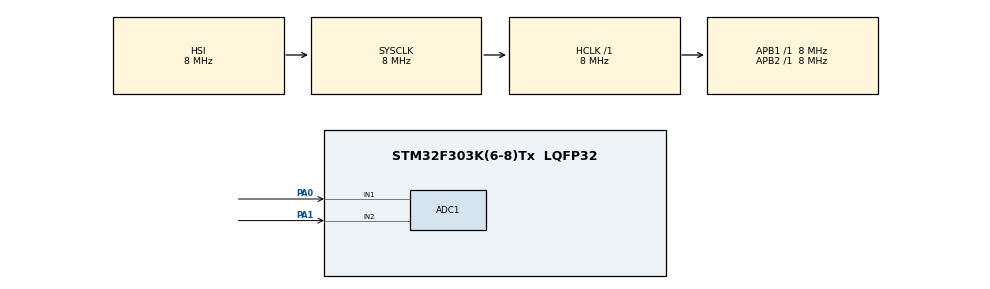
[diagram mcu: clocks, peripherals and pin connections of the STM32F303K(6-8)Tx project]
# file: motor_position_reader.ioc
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ADC1.Channel-0\#ChannelRegularConversion=ADC_CHANNEL_1
ADC1.Channel-2\#ChannelRegularConversion=ADC_CHANNEL_2
ADC1.ClockPrescaler=ADC_CLOCK_SYNC_PCLK_DIV1
ADC1.ContinuousConvMode=DISABLE
ADC1.DMAContinuousRequests=ENABLE
ADC1.EOCSelection=ADC_EOC_SEQ_CONV
ADC1.EnableAnalogWatchDog1=false
ADC1.EnableInjectedConversion=ENABLE
ADC1.ExternalTrigConv=ADC_EXTERNALTRIGCONV_T2_TRGO
ADC1.NbrOfConversion=2
ADC1.NbrOfConversionFlag=1
ADC1.Offset-0\#ChannelRegularConversion=0
ADC1.Offset-2\#ChannelRegularConversion=0
ADC1.OffsetNumber-0\#ChannelRegularConversion=ADC_OFFSET_NONE
ADC1.OffsetNumber-2\#ChannelRegularConversion=ADC_OFFSET_NONE
ADC1.Rank-0\#ChannelRegularConversion=1
ADC1.Rank-2\#ChannelRegularConversion=2
ADC1.SamplingTime-0\#ChannelRegularConversion=ADC_SAMPLETIME_19CYCLES_5
ADC1.SamplingTime-2\#ChannelRegularConversion=ADC_SAMPLETIME_19CYCLES_5
ADC1.SamplingTimeOPAMP-2\#ChannelRegularConversion=ADC_SAMPLETIME_4CYCLES_5
ADC1.SubFamily=STM32F303x8
ADC1.master=1
Dma.ADC1.0.Direction=DMA_PERIPH_TO_MEMORY
Dma.ADC1.0.Instance=DMA1_Channel1
Dma.ADC1.0.MemDataAlignment=DMA_MDATAALIGN_HALFWORD
Dma.ADC1.0.MemInc=DMA_MINC_ENABLE
Dma.ADC1.0.Mode=DMA_CIRCULAR
Dma.ADC1.0.PeriphDataAlignment=DMA_PDATAALIGN_HALFWORD
Dma.ADC1.0.PeriphInc=DMA_PINC_DISABLE
Dma.ADC1.0.Priority=DMA_PRIORITY_LOW
Dma.Request0=ADC1
Mcu.Family=STM32F3
Mcu.Name=STM32F303K(6-8)Tx
Mcu.Package=LQFP32
NVIC.DMA1_Channel1_IRQn=true\:0\:0\:false\:false\:true\:false\:true\:true
NVIC.PriorityGroup=NVIC_PRIORITYGROUP_4
PA0.Mode=IN1-Single-Ended
PA0.Signal=ADC1_IN1
PA1.Mode=IN2-Single-Ended
PA1.Signal=ADC1_IN2
PA13.Mode=Serial_Wire
PA13.Signal=SYS_JTMS-SWDIO
PA14.Mode=Serial_Wire
PA14.Signal=SYS_JTCK-SWCLK
ProjectManager.HeapSize=0x200
ProjectManager.StackSize=0x400
ProjectManager.TargetToolchain=STM32CubeIDE
RCC.AHBFreq_Value=8000000
RCC.APB1Freq_Value=8000000
RCC.APB2Freq_Value=8000000
RCC.CortexFreq_Value=8000000
RCC.HSE_VALUE=8000000
RCC.HSI_VALUE=8000000
RCC.SYSCLKFreq_VALUE=8000000
TIM2.Period=999
TIM2.Prescaler=7999
TIM2.TIM_MasterOutputTrigger=TIM_TRGO_UPDATE
TIM2.TIM_MasterSlaveMode=TIM_MASTERSLAVEMODE_ENABLE
VP_TIM2_VS_ClockSourceINT.Mode=Internal
board=custom

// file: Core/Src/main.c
/* USER CODE BEGIN Header */
/**
 ******************************************************************************
 * @file           : main.c
 * @brief          : Main program body
 ******************************************************************************
 * @attention
 *
 * Copyright (c) 2025 STMicroelectronics.
 * All rights reserved.
 *
 * This software is licensed under terms that can be found in the LICENSE file
 * in the root directory of this software component.
 * If no LICENSE file comes with this software, it is provided AS-IS.
 *
 ******************************************************************************
 */
/* USER CODE END Header */
#include "main.h"

/* USER CODE BEGIN PD */
#define ADC_BUF_SIZE	2
#define MOTOR_HISTORY_LEN	3 //PID only needs 3 max since it is at most second order
/* USER CODE END PD */

ADC_HandleTypeDef hadc1;
DMA_HandleTypeDef hdma_adc1;

TIM_HandleTypeDef htim2;

/* USER CODE BEGIN PV */
volatile uint8_t position_ready = 0; //flag representing whether or not position data is ready from adc
uint16_t raw_pos_values[ADC_BUF_SIZE];

uint16_t motor1_pos[MOTOR_HISTORY_LEN];
uint16_t motor2_pos[MOTOR_HISTORY_LEN];
/* USER CODE END PV */

void SystemClock_Config(void);
static void MX_GPIO_Init(void);
static void MX_DMA_Init(void);
static void MX_ADC1_Init(void);
static void MX_TIM2_Init(void);

int main(void)
{

	/* MCU Configuration--------------------------------------------------------*/

	/* Reset of all peripherals, Initializes the Flash interface and the Systick. */
	HAL_Init();

	/* Configure the system clock */
	SystemClock_Config();

	/* Initialize all configured peripherals */
	MX_GPIO_Init();
	MX_DMA_Init();
	MX_ADC1_Init();
	MX_TIM2_Init();
	/* USER CODE BEGIN 2 */
	if (HAL_TIM_Base_Start(&htim2) != HAL_OK)
	{
		Error_Handler();
	}

	if (HAL_ADCEx_Calibration_Start(&hadc1, ADC_SINGLE_ENDED) != HAL_OK) //calibrate ADC to get rid of offset error, Ex stands for extended. Special marking for function in HAL that might differ on other stm32 lines.
	{ //No Ex in HAL functions means you can easily copy code to other stm32 families.
		Error_Handler();
	}

	if (HAL_ADC_Start_DMA(&hadc1, (uint32_t*) raw_pos_values, 2) != HAL_OK)
	{
		Error_Handler();
	}
	/* USER CODE END 2 */

	/* Infinite loop */
	/* USER CODE BEGIN WHILE */
	while (1)
	{
		//The code updates the angle every 1 second, it is slow just for demo purposes. The analog output of the motor encoders will be connected to either pin A0 or A1.
		//The angle values will be in motor1_pos and motor2_pos. Must view live expressions and add these arrays to see the angles.
		while (!position_ready);
		position_ready = 0; //set flag back to 0

		/* USER CODE END WHILE */

	}
}

void SystemClock_Config(void)
{
	RCC_OscInitTypeDef RCC_OscInitStruct =
	{ 0 };
	RCC_ClkInitTypeDef RCC_ClkInitStruct =
	{ 0 };

	/** Initializes the RCC Oscillators according to the specified parameters
	 * in the RCC_OscInitTypeDef structure.
	 */
	RCC_OscInitStruct.OscillatorType = RCC_OSCILLATORTYPE_HSI;
	RCC_OscInitStruct.HSIState = RCC_HSI_ON;
	RCC_OscInitStruct.HSICalibrationValue = RCC_HSICALIBRATION_DEFAULT;
	RCC_OscInitStruct.PLL.PLLState = RCC_PLL_NONE;
	if (HAL_RCC_OscConfig(&RCC_OscInitStruct) != HAL_OK)
	{
		Error_Handler();
	}

	/** Initializes the CPU, AHB and APB buses clocks
	 */
	RCC_ClkInitStruct.ClockType = RCC_CLOCKTYPE_HCLK | RCC_CLOCKTYPE_SYSCLK
			| RCC_CLOCKTYPE_PCLK1 | RCC_CLOCKTYPE_PCLK2;
	RCC_ClkInitStruct.SYSCLKSource = RCC_SYSCLKSOURCE_HSI;
	RCC_ClkInitStruct.AHBCLKDivider = RCC_SYSCLK_DIV1;
	RCC_ClkInitStruct.APB1CLKDivider = RCC_HCLK_DIV1;
	RCC_ClkInitStruct.APB2CLKDivider = RCC_HCLK_DIV1;

	if (HAL_RCC_ClockConfig(&RCC_ClkInitStruct, FLASH_LATENCY_0) != HAL_OK)
	{
		Error_Handler();
	}
}

static void MX_ADC1_Init(void)
{

	ADC_MultiModeTypeDef multimode =
	{ 0 };
	ADC_ChannelConfTypeDef sConfig =
	{ 0 };

	/** Common config
	 */
	hadc1.Instance = ADC1;
	hadc1.Init.ClockPrescaler = ADC_CLOCK_SYNC_PCLK_DIV1;
	hadc1.Init.Resolution = ADC_RESOLUTION_12B;
	hadc1.Init.ScanConvMode = ADC_SCAN_ENABLE;
	hadc1.Init.ContinuousConvMode = DISABLE;
	hadc1.Init.DiscontinuousConvMode = DISABLE;
	hadc1.Init.ExternalTrigConvEdge = ADC_EXTERNALTRIGCONVEDGE_RISING;
	hadc1.Init.ExternalTrigConv = ADC_EXTERNALTRIGCONV_T2_TRGO;
	hadc1.Init.DataAlign = ADC_DATAALIGN_RIGHT;
	hadc1.Init.NbrOfConversion = 2;
	hadc1.Init.DMAContinuousRequests = ENABLE;
	hadc1.Init.EOCSelection = ADC_EOC_SEQ_CONV;
	hadc1.Init.LowPowerAutoWait = DISABLE;
	hadc1.Init.Overrun = ADC_OVR_DATA_OVERWRITTEN;
	if (HAL_ADC_Init(&hadc1) != HAL_OK)
	{
		Error_Handler();
	}

	/** Configure the ADC multi-mode
	 */
	multimode.Mode = ADC_MODE_INDEPENDENT;
	if (HAL_ADCEx_MultiModeConfigChannel(&hadc1, &multimode) != HAL_OK)
	{
		Error_Handler();
	}

	/** Configure Regular Channel
	 */
	sConfig.Channel = ADC_CHANNEL_1;
	sConfig.Rank = ADC_REGULAR_RANK_1;
	sConfig.SingleDiff = ADC_SINGLE_ENDED;
	sConfig.SamplingTime = ADC_SAMPLETIME_19CYCLES_5;
	sConfig.OffsetNumber = ADC_OFFSET_NONE;
	sConfig.Offset = 0;
	if (HAL_ADC_ConfigChannel(&hadc1, &sConfig) != HAL_OK)
	{
		Error_Handler();
	}

	/** Configure Regular Channel
	 */
	sConfig.Channel = ADC_CHANNEL_2;
	sConfig.Rank = ADC_REGULAR_RANK_2;
	if (HAL_ADC_ConfigChannel(&hadc1, &sConfig) != HAL_OK)
	{
		Error_Handler();
	}

}

static void MX_TIM2_Init(void)
{

	TIM_ClockConfigTypeDef sClockSourceConfig =
	{ 0 };
	TIM_MasterConfigTypeDef sMasterConfig =
	{ 0 };

	htim2.Instance = TIM2;
	htim2.Init.Prescaler = 7999;
	htim2.Init.CounterMode = TIM_COUNTERMODE_UP;
	htim2.Init.Period = 999;
	htim2.Init.ClockDivision = TIM_CLOCKDIVISION_DIV1;
	htim2.Init.AutoReloadPreload = TIM_AUTORELOAD_PRELOAD_DISABLE;
	if (HAL_TIM_Base_Init(&htim2) != HAL_OK)
	{
		Error_Handler();
	}
	sClockSourceConfig.ClockSource = TIM_CLOCKSOURCE_INTERNAL;
	if (HAL_TIM_ConfigClockSource(&htim2, &sClockSourceConfig) != HAL_OK)
	{
		Error_Handler();
	}
	sMasterConfig.MasterOutputTrigger = TIM_TRGO_UPDATE;
	sMasterConfig.MasterSlaveMode = TIM_MASTERSLAVEMODE_ENABLE;
	if (HAL_TIMEx_MasterConfigSynchronization(&htim2, &sMasterConfig) != HAL_OK)
	{
		Error_Handler();
	}

}

static void MX_DMA_Init(void)
{

	/* DMA controller clock enable */
	__HAL_RCC_DMA1_CLK_ENABLE();

	/* DMA interrupt init */
	/* DMA1_Channel1_IRQn interrupt configuration */
	HAL_NVIC_SetPriority(DMA1_Channel1_IRQn, 0, 0);
	HAL_NVIC_EnableIRQ(DMA1_Channel1_IRQn);

}

static void MX_GPIO_Init(void)
{

	/* GPIO Ports Clock Enable */
	__HAL_RCC_GPIOA_CLK_ENABLE();

}

/* USER CODE BEGIN 4 */
void HAL_ADC_ConvCpltCallback(ADC_HandleTypeDef *hadc) //once buffer is full, stop the ADC
{
	for (int delay = MOTOR_HISTORY_LEN - 1; delay > 0; --delay) //shift all elements to right
	{
		motor1_pos[delay] = motor1_pos[delay - 1];
		motor2_pos[delay] = motor2_pos[delay - 1];
	}
	motor1_pos[0] = raw_pos_values[0] * 0.08789; //multiply by 360/4096 to convert ADC steps to angle in degrees
	motor2_pos[0] = raw_pos_values[1] * 0.08789;

	position_ready = 1; //signal to main loop that adc data ready
}
/* USER CODE END 4 */

void Error_Handler(void)
{
	__disable_irq();
	while (1)
	{
	}
}
